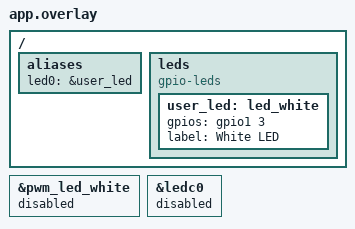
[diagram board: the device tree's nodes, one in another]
#include <zephyr/dt-bindings/gpio/gpio.h>

/ {
	aliases {
		led0 = &user_led;
	};

	leds {
		compatible = "gpio-leds";
		user_led: led_white {
			gpios = <&gpio1 3 GPIO_ACTIVE_HIGH>;
			label = "White LED";
		};
	};

};
&pwm_led_white {
	status = "disabled";
};

&ledc0 {
	status = "disabled";
};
